AUTOSAR XML (schema 4-2-2)
package /ParkSWC
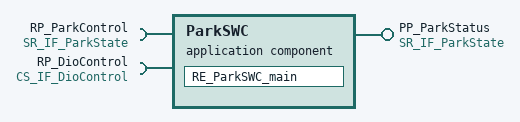
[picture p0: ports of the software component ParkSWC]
  application sw component type ParkSWC
    provide port PP_ParkStatus: provided-interface=SR_IF_ParkState
    require port RP_ParkControl: required-interface=SR_IF_ParkState
    require port RP_DioControl: required-interface=CS_IF_DioControl
    behavior SwcInternalBehavior: data-type-mapping=DataTypeMappingSet
      data received event DRE_RE_ParkSWC_main: start-on-event=RE_ParkSWC_main, data=RP_ParkControl.DE_ParkState
      runnable RE_ParkSWC_main
        data-receive-point-by-arguments:
          access DRPA_DE_ParkState_0: accessed-variable=RP_ParkControl.DE_ParkState
        data-send-points:
          access DSP_DE_ParkState_0: accessed-variable=PP_ParkStatus.DE_ParkState
        sync call SynchronousServerCallPoint_0: operation=RP_DioControl.DioActuate
